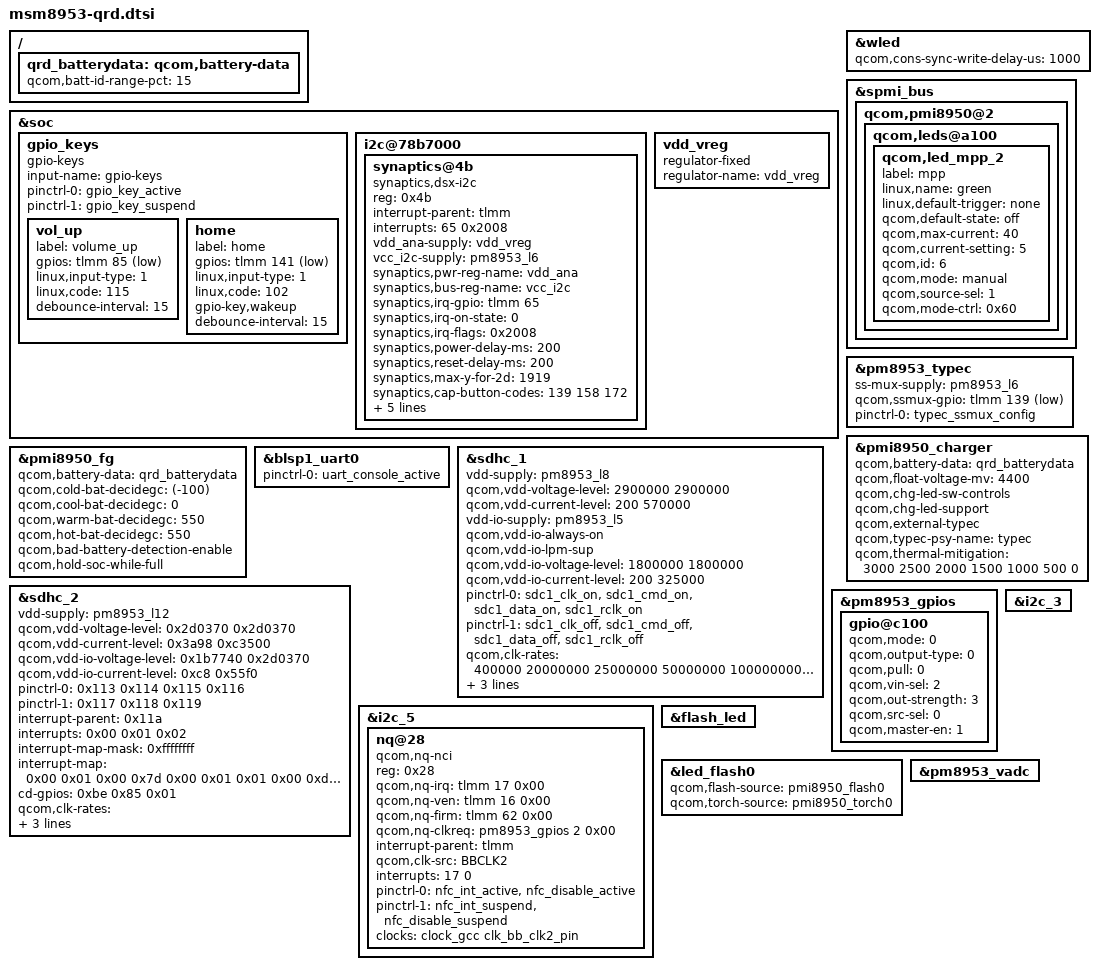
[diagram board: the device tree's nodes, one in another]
/*
 * Copyright (c) 2015-2016, The Linux Foundation. All rights reserved.
 *
 * This program is free software; you can redistribute it and/or modify
 * it under the terms of the GNU General Public License version 2 and
 * only version 2 as published by the Free Software Foundation.
 *
 * This program is distributed in the hope that it will be useful,
 * but WITHOUT ANY WARRANTY; without even the implied warranty of
 * MERCHANTABILITY or FITNESS FOR A PARTICULAR PURPOSE.  See the
 * GNU General Public License for more details.
 */

#include "msm8953-pinctrl.dtsi"
#include "msm8953-camera-sensor-qrd.dtsi"

&soc {
	gpio_keys {
		compatible = "gpio-keys";
		input-name = "gpio-keys";
		pinctrl-names = "tlmm_gpio_key_active","tlmm_gpio_key_suspend";
		pinctrl-0 = <&gpio_key_active>;
		pinctrl-1 = <&gpio_key_suspend>;

		vol_up {
			label = "volume_up";
			gpios = <&tlmm 85 0x1>;
			linux,input-type = <1>;
			linux,code = <115>;
			debounce-interval = <15>;
		};
        home {
				label = "home";
				gpios = <&tlmm 141 0x1>;
				linux,input-type = <1>;
				linux,code = <102>;
				gpio-key,wakeup;
				debounce-interval = <15>;
        };
	};

	i2c@78b7000 { /* BLSP1 QUP3 */
		status = "okay";
		synaptics@4b {
			compatible = "synaptics,dsx-i2c";
			reg = <0x4b>;
			interrupt-parent = <&tlmm>;
			interrupts = <65 0x2008>;
			vdd_ana-supply = <&vdd_vreg>;
			vcc_i2c-supply = <&pm8953_l6>;
			synaptics,pwr-reg-name = "vdd_ana";
			synaptics,bus-reg-name = "vcc_i2c";
			synaptics,irq-gpio = <&tlmm 65 0x2008>;
			synaptics,irq-on-state = <0>;
			synaptics,irq-flags = <0x2008>;
			synaptics,power-delay-ms = <200>;
			synaptics,reset-delay-ms = <200>;
			synaptics,max-y-for-2d = <1919>;
			synaptics,cap-button-codes = <139 158 172>;
			synaptics,vir-button-codes = <139 180 2000 320 160
						      158 540 2000 320 160
						      172 900 2000 320 160>;
			synaptics,resume-in-workqueue;
			/* Underlying clocks used by secure touch */
			clock-names = "iface_clk", "core_clk";
			clocks = <&clock_gcc clk_gcc_blsp1_ahb_clk>,
				<&clock_gcc clk_gcc_blsp1_qup3_i2c_apps_clk>;
		};
	};

	vdd_vreg: vdd_vreg {
		compatible = "regulator-fixed";
		status = "ok";
		regulator-name = "vdd_vreg";
	};
};

&wled {
	qcom,cons-sync-write-delay-us = <1000>;
};

&spmi_bus {
	qcom,pmi8950@2 {
		qcom,leds@a100 {
			status = "okay";
			qcom,led_mpp_2 {
				label = "mpp";
				linux,name = "green";
				linux,default-trigger = "none";
				qcom,default-state = "off";
				qcom,max-current = <40>;
				qcom,current-setting = <5>;
				qcom,id = <6>;
				qcom,mode = "manual";
				qcom,source-sel = <1>;
				qcom,mode-ctrl = <0x60>;
			};
		};
	};
};

/ {
	qrd_batterydata: qcom,battery-data {
		qcom,batt-id-range-pct = <15>;
		#include "batterydata-qrd-sku1-4v4-2800mah.dtsi"
	};
};

&pm8953_typec {
	ss-mux-supply = <&pm8953_l6>;
	qcom,ssmux-gpio = <&tlmm 139 GPIO_ACTIVE_LOW>;
	pinctrl-names = "default";
	pinctrl-0 = <&typec_ssmux_config>;
};

&pmi8950_charger {
	qcom,battery-data = <&qrd_batterydata>;
	qcom,float-voltage-mv = <4400>;
	qcom,chg-led-sw-controls;
	qcom,chg-led-support;
	qcom,external-typec;
	qcom,typec-psy-name = "typec";
	qcom,thermal-mitigation = <3000 2500 2000 1500 1000 500 0>;
	status = "okay";
};

&pmi8950_fg {
	qcom,battery-data = <&qrd_batterydata>;
	qcom,cold-bat-decidegc = <(-100)>;
	qcom,cool-bat-decidegc = <0>;
	qcom,warm-bat-decidegc = <550>;
	qcom,hot-bat-decidegc = <550>;
	qcom,bad-battery-detection-enable;
	qcom,hold-soc-while-full;
};

&blsp1_uart0 {
	status = "ok";
	pinctrl-names = "default";
	pinctrl-0 = <&uart_console_active>;
};

&sdhc_1 {
	/* device core power supply */
	vdd-supply = <&pm8953_l8>;
	qcom,vdd-voltage-level = <2900000 2900000>;
	qcom,vdd-current-level = <200 570000>;

	/* device communication power supply */
	vdd-io-supply = <&pm8953_l5>;
	qcom,vdd-io-always-on;
	qcom,vdd-io-lpm-sup;
	qcom,vdd-io-voltage-level = <1800000 1800000>;
	qcom,vdd-io-current-level = <200 325000>;

	pinctrl-names = "active", "sleep";
	pinctrl-0 = <&sdc1_clk_on &sdc1_cmd_on &sdc1_data_on &sdc1_rclk_on>;
	pinctrl-1 = <&sdc1_clk_off &sdc1_cmd_off &sdc1_data_off &sdc1_rclk_off>;

	qcom,clk-rates = <400000 20000000 25000000 50000000 100000000 192000000
								384000000>;
	qcom,nonremovable;
	qcom,bus-speed-mode = "HS400_1p8v", "HS200_1p8v", "DDR_1p8v";

	status = "ok";
};

&sdhc_2 {
	/* device core power supply */
	vdd-supply = <&pm8953_l11>;
	qcom,vdd-voltage-level = <0x2d0370 0x2d0370>;
    qcom,vdd-current-level = <0x3a98 0xc3500>;

	/* device communication power supply */
	vdd-supply = <&pm8953_l12>;
    qcom,vdd-io-voltage-level = <0x1b7740 0x2d0370>;
    qcom,vdd-io-current-level = <0xc8 0x55f0>;

	pinctrl-names = "active", "sleep";
	pinctrl-0 = <0x113 0x114 0x115 0x116>;
	pinctrl-1 = <0x117 0x118 0x119>;
    
	#address-cells = <0>;
	interrupt-parent = <0x11a>;
	interrupts = <0x00 0x01 0x02>;
	#interrupt-cells = <1>;
	interrupt-map-mask = <0xffffffff>;
	interrupt-map = <0x00 0x01 0x00 0x7d 0x00 0x01 0x01 0x00 0xdd 0x00 0x02 0xbe 0x85 0x00>;
	interrupt-names = "hc_irq", "pwr_irq", "status_irq";
	cd-gpios = <0xbe 0x85 0x01>;

	qcom,clk-rates = <0x61a80 0x1312d00 0x17d7840 0x2faf080 0x5f5e100 0xbebc200>;
    qcom,bus-speed-mode = "SDR12","SDR25","SDR50","DDR50","SDR104";
    
	status = "ok";
};

&i2c_5 { /* BLSP2 QUP1 (NFC) */
	nq@28 {
		compatible = "qcom,nq-nci";
		reg = <0x28>;
		qcom,nq-irq = <&tlmm 17 0x00>;
		qcom,nq-ven = <&tlmm 16 0x00>;
		qcom,nq-firm = <&tlmm 62 0x00>;
		qcom,nq-clkreq = <&pm8953_gpios 2 0x00>;
		interrupt-parent = <&tlmm>;
		qcom,clk-src = "BBCLK2";
		interrupts = <17 0>;
		interrupt-names = "nfc_irq";
		pinctrl-names = "nfc_active", "nfc_suspend";
		pinctrl-0 = <&nfc_int_active &nfc_disable_active>;
		pinctrl-1 = <&nfc_int_suspend &nfc_disable_suspend>;
		clocks = <&clock_gcc clk_bb_clk2_pin>;
		clock-names = "ref_clk";
	};
};

&pm8953_gpios {
	/* GPIO 2 (NFC_CLK_REQ) */
	gpio@c100 {
		qcom,mode = <0>;
		qcom,output-type = <0>;
		qcom,pull = <0>;
		qcom,vin-sel = <2>;
		qcom,out-strength = <3>;
		qcom,src-sel = <0>;
		qcom,master-en = <1>;
		status = "okay";
	};
};

&i2c_3 {
	status = "ok";
};

&flash_led {
	/delete-node/ qcom,flash_1;
	/delete-node/ qcom,torch_1;
};

&led_flash0{
	qcom,flash-source = <&pmi8950_flash0>;
	qcom,torch-source = <&pmi8950_torch0>;
};

&pm8953_vadc {
	/delete-node/ chan@11;
};
